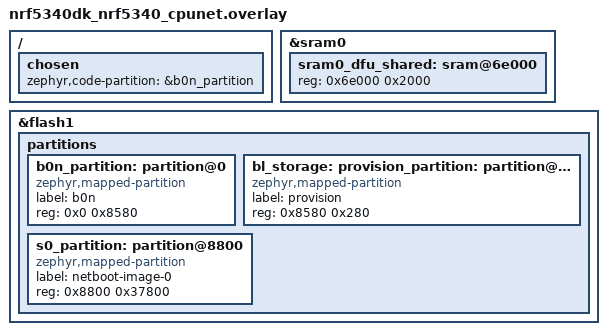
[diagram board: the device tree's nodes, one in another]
/*
 * Copyright (c) 2024 Nordic Semiconductor ASA
 *
 * SPDX-License-Identifier: LicenseRef-Nordic-5-Clause
 */

/delete-node/ &boot_partition;
/delete-node/ &slot0_partition;
/delete-node/ &slot1_partition;
/delete-node/ &storage_partition;

/ {
	chosen {
		zephyr,code-partition = &b0n_partition;
	};
};

/* Keep sram0_dfu_shared in lock-step with the cpuapp side.
 *
 * The upstream nrf5340_shared_sram_partition.dtsi places sram0_dfu_shared at
 * offset 0x0 of sram0 (absolute 0x20000000). On the cpuapp side we relocate
 * it to 0x2006e000 (inside sram0_ns), both to stay out of sram0_s (TF-M's
 * secure SRAM) and to avoid the MCUboot pcd_lock_ram() window where that
 * region is temporarily configured as read-only/non-secure.
 *
 * b0n must use the exact same absolute address so that TF-M's
 * pcd_write_cmd_lock_debug() on cpuapp and the PCD read on cpunet land on the
 * same bytes. Otherwise b0n reads 0x20000000 while cpuapp writes 0x2006e000,
 * which triggers SPU.RAMACCERR on cpuapp (non-secure access into sram0_s by
 * the network core) the moment b0n starts up.
 */
/delete-node/ &sram0_dfu_shared;

&sram0 {
	sram0_dfu_shared: sram@6e000 {
		reg = <0x6e000 0x2000>;
	};
};

&flash1 {
	partitions {
		b0n_partition: partition@0 {
			compatible = "zephyr,mapped-partition";
			label = "b0n";
			reg = <0x0 0x8580>;
		};

		bl_storage: provision_partition: partition@8580 {
			compatible = "zephyr,mapped-partition";
			label = "provision";
			reg = <0x8580 0x280>;
		};

		s0_partition: partition@8800 {
			compatible = "zephyr,mapped-partition";
			label = "netboot-image-0";
			reg = <0x8800 0x37800>;
		};
	};
};
